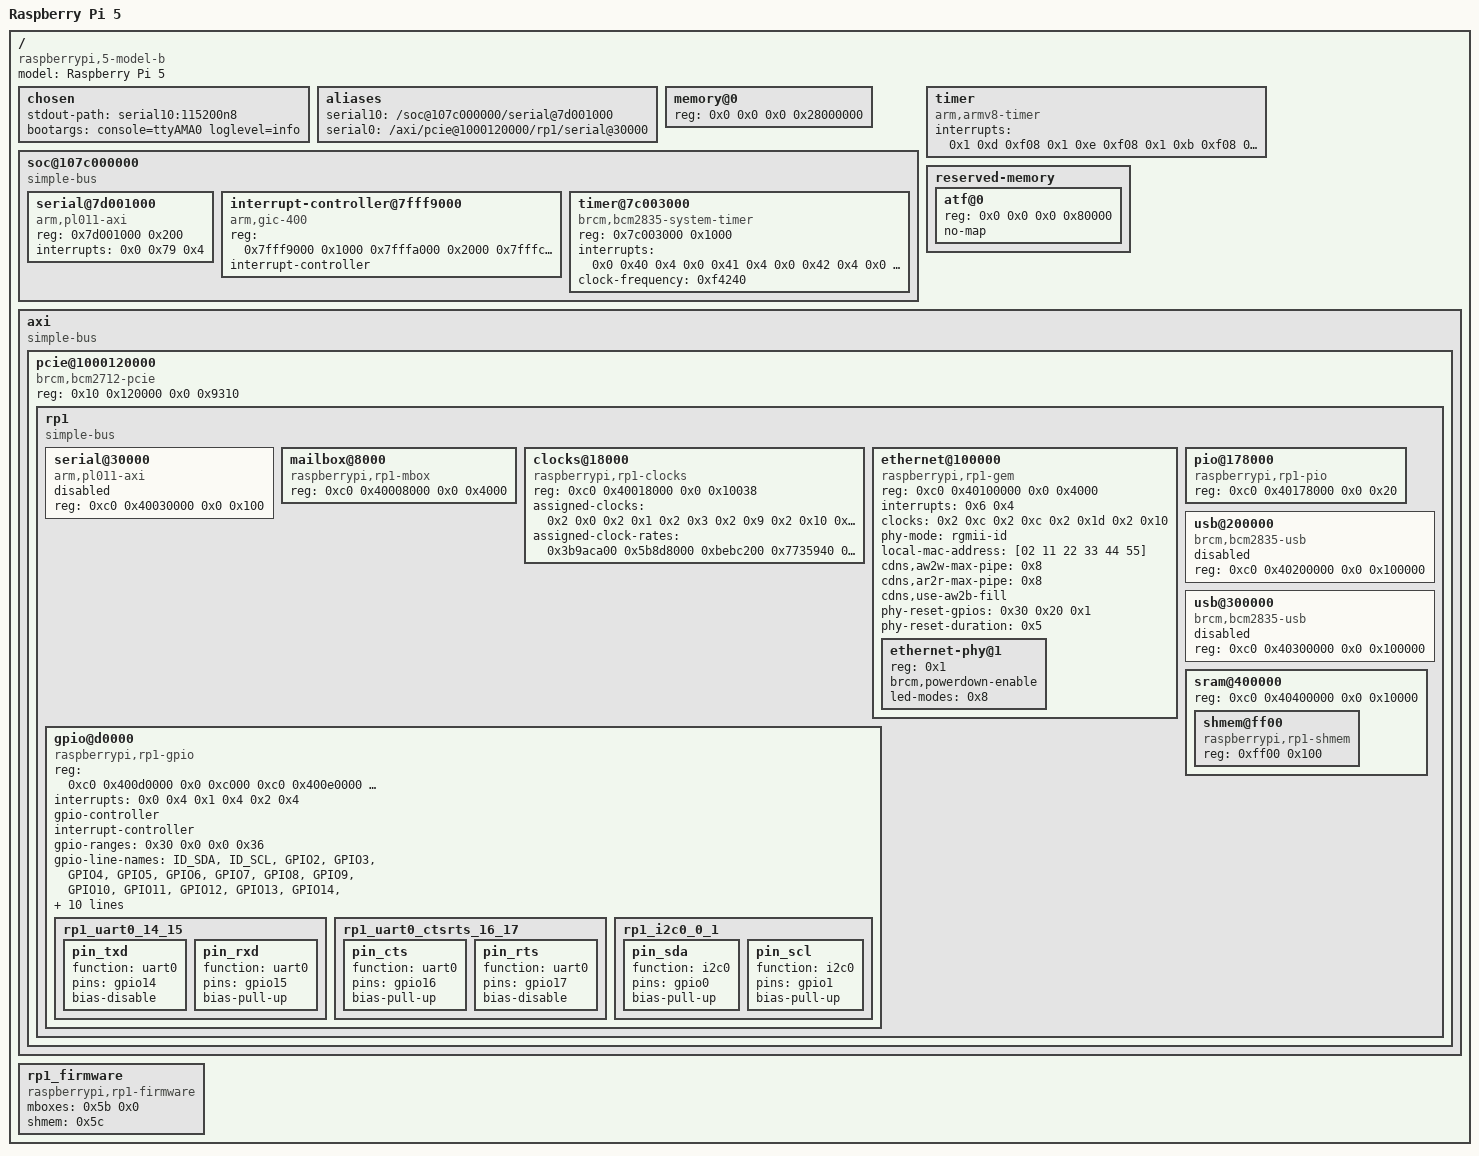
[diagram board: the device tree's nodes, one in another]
// SPDX-License-Identifier: BSD-3-Clause
// Generated by tests/fixtures/pi5/generate.py; values from the official Pi 5 DTB.
/dts-v1/;

/ {
    compatible = "raspberrypi,5-model-b", "brcm,bcm2712";
    model = "Raspberry Pi 5";
    #address-cells = <0x2>;
    #size-cells = <0x2>;
    chosen {
        stdout-path = "serial10:115200n8";
        bootargs = "console=ttyAMA0 loglevel=info";
    };
    aliases {
        serial10 = "/soc@107c000000/serial@7d001000";
        serial0 = "/axi/pcie@1000120000/rp1/serial@30000";
    };
    memory@0 {
        device_type = "memory";
        reg = <0x0 0x0 0x0 0x28000000>;
    };
    soc@107c000000 {
        compatible = "simple-bus";
        #address-cells = <0x1>;
        #size-cells = <0x1>;
        ranges = <0x0 0x10 0x0 0x80000000>;
        serial@7d001000 {
            compatible = "arm,pl011-axi", "arm,pl011", "arm,primecell";
            reg = <0x7d001000 0x200>;
            interrupts = <0x0 0x79 0x4>;
            status = "okay";
        };
        interrupt-controller@7fff9000 {
            compatible = "arm,gic-400";
            reg = <0x7fff9000 0x1000 0x7fffa000 0x2000 0x7fffc000 0x2000 0x7fffe000 0x2000>;
            interrupt-controller;
            #interrupt-cells = <0x3>;
        };
        timer@7c003000 {
            compatible = "brcm,bcm2835-system-timer";
            reg = <0x7c003000 0x1000>;
            interrupts = <0x0 0x40 0x4 0x0 0x41 0x4 0x0 0x42 0x4 0x0 0x43 0x4>;
            clock-frequency = <0xf4240>;
        };
    };
    timer {
        compatible = "arm,armv8-timer";
        interrupts = <0x1 0xd 0xf08 0x1 0xe 0xf08 0x1 0xb 0xf08 0x1 0xa 0xf08>;
    };
    reserved-memory {
        #address-cells = <0x2>;
        #size-cells = <0x2>;
        ranges = <>;
        atf@0 {
            reg = <0x0 0x0 0x0 0x80000>;
            no-map;
        };
    };
    axi {
        compatible = "simple-bus";
        #address-cells = <0x2>;
        #size-cells = <0x2>;
        pcie@1000120000 {
            compatible = "brcm,bcm2712-pcie";
            reg = <0x10 0x120000 0x0 0x9310>;
            device_type = "pci";
            #address-cells = <0x3>;
            #size-cells = <0x2>;
            ranges = <0x2000000 0x0 0x0 0x1f 0x0 0x0 0xfffffffc 0x43000000 0x4 0x0 0x1c 0x0 0x3 0x0>;
            status = "okay";
            rp1 {
                compatible = "simple-bus";
                #address-cells = <0x2>;
                #size-cells = <0x2>;
                ranges = <0xc0 0x40000000 0x2000000 0x0 0x0 0x0 0x410000>;
                serial@30000 {
                    compatible = "arm,pl011-axi", "arm,pl011";
                    reg = <0xc0 0x40030000 0x0 0x100>;
                    status = "disabled";
                };
                mailbox@8000 {
                    compatible = "raspberrypi,rp1-mbox";
                    reg = <0xc0 0x40008000 0x0 0x4000>;
                    status = "okay";
                    phandle = <0x5b>;
                };
                clocks@18000 {
                    compatible = "raspberrypi,rp1-clocks";
                    reg = <0xc0 0x40018000 0x0 0x10038>;
                    #clock-cells = <0x1>;
                    phandle = <0x2>;
                    assigned-clocks = <0x2 0x0 0x2 0x1 0x2 0x3 0x2 0x9 0x2 0x10 0x2 0x4 0x2 0xa 0x2 0xc 0x2 0x6 0x2 0xd 0x2 0x1f 0x2 0x20 0x2 0x1d>;
                    assigned-clock-rates = <0x3b9aca00 0x5b8d8000 0xbebc200 0x7735940 0x7735940 0x3a98000 0x927c000 0xbebc200 0x5f5e100 0x2faf080 0xf4240 0xbebc200 0x2faf080>;
                };
                ethernet@100000 {
                    compatible = "raspberrypi,rp1-gem", "cdns,macb";
                    reg = <0xc0 0x40100000 0x0 0x4000>;
                    #address-cells = <0x1>;
                    #size-cells = <0x0>;
                    interrupts = <0x6 0x4>;
                    clocks = <0x2 0xc 0x2 0xc 0x2 0x1d 0x2 0x10>;
                    clock-names = "pclk", "hclk", "tsu_clk", "tx_clk";
                    phy-mode = "rgmii-id";
                    local-mac-address = [02 11 22 33 44 55];
                    cdns,aw2w-max-pipe = <0x8>;
                    cdns,ar2r-max-pipe = <0x8>;
                    cdns,use-aw2b-fill;
                    phy-reset-gpios = <0x30 0x20 0x1>;
                    phy-reset-duration = <0x5>;
                    status = "okay";
                    ethernet-phy@1 {
                        reg = <0x1>;
                        brcm,powerdown-enable;
                        led-modes = <0x8>;
                    };
                };
                gpio@d0000 {
                    compatible = "raspberrypi,rp1-gpio";
                    reg = <0xc0 0x400d0000 0x0 0xc000 0xc0 0x400e0000 0x0 0xc000 0xc0 0x400f0000 0x0 0xc000>;
                    interrupts = <0x0 0x4 0x1 0x4 0x2 0x4>;
                    gpio-controller;
                    #gpio-cells = <0x2>;
                    interrupt-controller;
                    #interrupt-cells = <0x2>;
                    gpio-ranges = <0x30 0x0 0x0 0x36>;
                    gpio-line-names = "ID_SDA", "ID_SCL", "GPIO2", "GPIO3", "GPIO4", "GPIO5", "GPIO6", "GPIO7", "GPIO8", "GPIO9", "GPIO10", "GPIO11", "GPIO12", "GPIO13", "GPIO14", "GPIO15", "GPIO16", "GPIO17", "GPIO18", "GPIO19", "GPIO20", "GPIO21", "GPIO22", "GPIO23", "GPIO24", "GPIO25", "GPIO26", "GPIO27", "PCIE_RP1_WAKE", "FAN_TACH", "HOST_SDA", "HOST_SCL", "ETH_RST_N", "-", "CD0_IO0_MICCLK", "CD0_IO0_MICDAT0", "RP1_PCIE_CLKREQ_N", "-", "CD0_SDA", "CD0_SCL", "CD1_SDA", "CD1_SCL", "USB_VBUS_EN", "USB_OC_N", "RP1_STAT_LED", "FAN_PWM", "CD1_IO0_MICCLK", "2712_WAKE", "CD1_IO1_MICDAT1", "EN_MAX_USB_CUR", "-", "-", "-", "-";
                    status = "okay";
                    phandle = <0x30>;
                    rp1_uart0_14_15 {
                        pin_txd {
                            function = "uart0";
                            pins = "gpio14";
                            bias-disable;
                        };
                        pin_rxd {
                            function = "uart0";
                            pins = "gpio15";
                            bias-pull-up;
                        };
                    };
                    rp1_uart0_ctsrts_16_17 {
                        pin_cts {
                            function = "uart0";
                            pins = "gpio16";
                            bias-pull-up;
                        };
                        pin_rts {
                            function = "uart0";
                            pins = "gpio17";
                            bias-disable;
                        };
                    };
                    rp1_i2c0_0_1 {
                        pin_sda {
                            function = "i2c0";
                            pins = "gpio0";
                            bias-pull-up;
                        };
                        pin_scl {
                            function = "i2c0";
                            pins = "gpio1";
                            bias-pull-up;
                        };
                    };
                };
                pio@178000 {
                    compatible = "raspberrypi,rp1-pio";
                    reg = <0xc0 0x40178000 0x0 0x20>;
                    status = "okay";
                };
                usb@200000 {
                    compatible = "brcm,bcm2835-usb";
                    reg = <0xc0 0x40200000 0x0 0x100000>;
                    status = "disabled";
                };
                usb@300000 {
                    compatible = "brcm,bcm2835-usb";
                    reg = <0xc0 0x40300000 0x0 0x100000>;
                    status = "disabled";
                };
                sram@400000 {
                    reg = <0xc0 0x40400000 0x0 0x10000>;
                    #address-cells = <0x1>;
                    #size-cells = <0x1>;
                    ranges = <0x0 0xc0 0x40400000 0x10000>;
                    shmem@ff00 {
                        compatible = "raspberrypi,rp1-shmem";
                        reg = <0xff00 0x100>;
                        phandle = <0x5c>;
                    };
                };
            };
        };
    };
    rp1_firmware {
        compatible = "raspberrypi,rp1-firmware", "simple-mfd";
        mboxes = <0x5b 0x0>;
        shmem = <0x5c>;
        phandle = <0x41>;
    };
};
